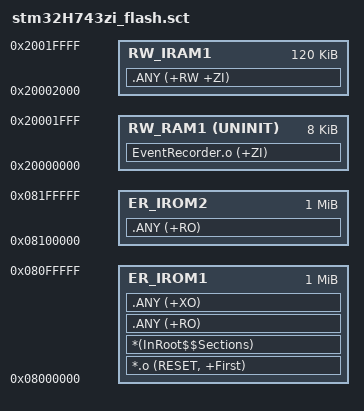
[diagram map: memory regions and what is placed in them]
; *************************************************************
; *** Scatter-Loading Description File generated by uVision ***
; *************************************************************

LR_IROM1 0x08000000 0x00100000  {    ; load region size_region
  ER_IROM1 0x08000000 0x00100000  {  ; load address = execution address
   *.o (RESET, +First)
   *(InRoot$$Sections)
   .ANY (+RO)
   .ANY (+XO)
  }
  RW_IRAM1 0x20002000 0x0001E000  {  ; RW data
   .ANY (+RW +ZI)
  }
  RW_RAM1 0x20000000 UNINIT 0x00002000  {
    EventRecorder.o (+ZI)
  }
}

LR_IROM2 0x08100000 0x00100000  {
  ER_IROM2 0x08100000 0x00100000  {  ; load address = execution address
   .ANY (+RO)
  }
}
